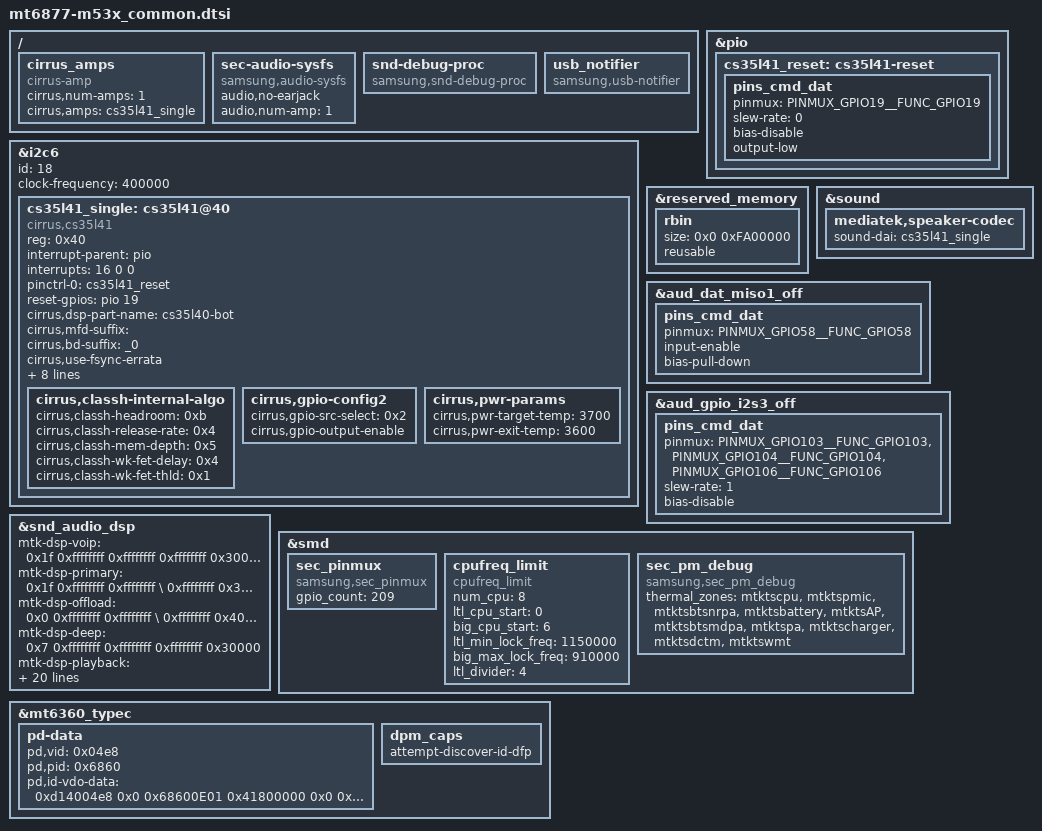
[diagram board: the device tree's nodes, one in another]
/* Generated by Samsung for MTK vendor board
 * If these files should be changed, then please make a sync with MTK
*/

/* Add Samsung configuration over here */
#include "display_lcd_m53x_common.dtsi"

/ {
	fragment@model {
		target-path = "/";
		__overlay__ {
			cirrus_amps {
				compatible = "cirrus-amp";
				cirrus,num-amps = <1>;
				cirrus,amps = <&cs35l41_single>;
			};

			sec-audio-sysfs {
				compatible = "samsung,audio-sysfs";
				status = "okay";
				audio,no-earjack;
				audio,num-amp = <1>;
			};

			snd-debug-proc {
				compatible = "samsung,snd-debug-proc";
				status = "okay";
			};

			usb_notifier {
				compatible = "samsung,usb-notifier";
			};
		};
	};
};

&pio {
	cs35l41_reset: cs35l41-reset {
		pins_cmd_dat {
			pinmux = <PINMUX_GPIO19__FUNC_GPIO19>;
			slew-rate = <0>;
			bias-disable;
			output-low;
		};
	};
};

&i2c6 {
	status = "okay";
	id = <18>;
	clock-frequency = <400000>;
	#address-cells = <1>;
	#size-cells = <0>;

	cs35l41_single: cs35l41@40 {
		#sound-dai-cells = <0>;
		compatible = "cirrus,cs35l41";
		reg = <0x40>;
		interrupt-parent = <&pio>;
		interrupts = <16 0 0>;
		pinctrl-names = "default";
		pinctrl-0 = <&cs35l41_reset>;
		reset-gpios = <&pio 19 0>;
		//VA-supply = <&l2_reg>;
		//VP-supply = <&vbat>;

		cirrus,dsp-part-name = "cs35l40-bot";
		cirrus,mfd-suffix = "";
		cirrus,bd-suffix = "_0";
		cirrus,use-fsync-errata;
		cirrus,bd-max-temp = <110>;

		//cirrus,asp-sdout-hiz = <0x3>;

		cirrus,dsp-noise-gate-enable;
		cirrus,dsp-noise-gate-delay = <0x4>;
		cirrus,dsp-noise-gate-threshold = <0x6>;

		cirrus,hw-noise-gate-select = <0x3F>;
		cirrus,hw-noise-gate-delay = <0x4>;
		cirrus,hw-noise-gate-threshold = <0x6>;

		cirrus,boost-peak-milliamp = <4100>;

		cirrus,classh-internal-algo {
			cirrus,classh-headroom = <0xb>;
			cirrus,classh-release-rate = <0x4>;
			cirrus,classh-mem-depth = <0x5>;
			cirrus,classh-wk-fet-delay = <0x4>;
			cirrus,classh-wk-fet-thld = <0x1>;
		};

		cirrus,gpio-config2 {
			cirrus,gpio-src-select = <0x2>;
			cirrus,gpio-output-enable;
		};

		cirrus,pwr-params {
			/* cirrus,pwr-global-enable; */
			cirrus,pwr-target-temp = <3700>;
			cirrus,pwr-exit-temp = <3600>;
		};
	};
};

&reserved_memory {
	rbin: rbin {
		size = <0x0 0xFA00000>;
		reusable;
	};
};

&sound {
	mediatek,speaker-codec {
		sound-dai = <&cs35l41_single>;
	};
};

&aud_dat_miso1_off {
	pins_cmd_dat {
		pinmux = <PINMUX_GPIO58__FUNC_GPIO58>;
		input-enable;
		bias-pull-down;
	};
};

&aud_gpio_i2s3_off {
	pins_cmd_dat {
		pinmux = <PINMUX_GPIO103__FUNC_GPIO103>,
			 <PINMUX_GPIO104__FUNC_GPIO104>,
			 <PINMUX_GPIO106__FUNC_GPIO106>;
		slew-rate = <1>;
		bias-disable;
	};
};

&snd_audio_dsp {
	mtk-dsp-voip = <0x1f 0xffffffff 0xffffffff 0xffffffff 0x30000>;
	mtk-dsp-primary = <0x1f 0xffffffff 0xffffffff \
			   0xffffffff 0x30000>;
	mtk-dsp-offload = <0x0 0xffffffff 0xffffffff \
			   0xffffffff 0x400000>;
	mtk-dsp-deep = <0x7 0xffffffff 0xffffffff 0xffffffff 0x30000>;
	mtk-dsp-playback = <0x1 0x4 0xffffffff 0x14 0x30000>;
	mtk-dsp-music = <0x1 0xffffffff 0xffffffff 0xffffffff 0x0>;
	mtk-dsp-capture1 = <0x1 0xffffffff 0xd 0x13 0x20000>;
	mtk-dsp-a2dp = <0x1 0xffffffff 0xffffffff 0xffffffff 0x40000>;
	mtk-dsp-dataprovider = <0x0 0xffffffff 0xf 0xffffffff 0x30000>;
	mtk-dsp-call-final = <0x0 0x4 0x10 0x14 0x18000>;
	mtk-dsp-fast = <0x5 0xffffffff 0xffffffff 0xffffffff 0x5000>;
	mtk-dsp-ktv = <0x1 0x8 0x12 0xffffffff 0x10000>;
	mtk-dsp-capture-raw = <0x0 0xffffffff 0xffffffff 0xffffffff 0x20000>;
	mtk-dsp-fm = <0x1 0xffffffff 0x10 0xffffffff 0x10000>;
	mtk-dsp-ver = <0x1>;
	swdsp-smartpa-process-enable = <0x0>;
	mtk-dsp-mem-afe = <0x1 0x40000>; /* always enable */
};

&smd {
	sec_pinmux {
		status = "okay";
		compatible = "samsung,sec_pinmux";
		gpio_count = <209>;
	};

	cpufreq_limit {
		status = "okay";
		compatible = "cpufreq_limit";

		num_cpu = <8>;
		ltl_cpu_start = <0>;
		big_cpu_start = <6>;
		ltl_min_lock_freq = <1150000>;
		big_max_lock_freq = <910000>;
		ltl_divider = <4>;
	};

	sec_pm_debug {
	status = "okay";
	compatible = "samsung,sec_pm_debug";

	thermal_zones = "mtktscpu", "mtktspmic", "mtktsbtsnrpa", "mtktsbattery",
					"mtktsAP", "mtktsbtsmdpa", "mtktspa", "mtktscharger",
					"mtktsdctm", "mtktswmt";
	};
};

&mt6360_typec {
	pd-data {
		pd,vid = <0x04e8>;
		pd,pid = <0x6860>;
		pd,id-vdo-data = <0xd14004e8 0x0 0x68600E01
				 0x41800000 0x0 0x21800000>;
	};

	dpm_caps {
		attempt-discover-id-dfp;
	};
};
